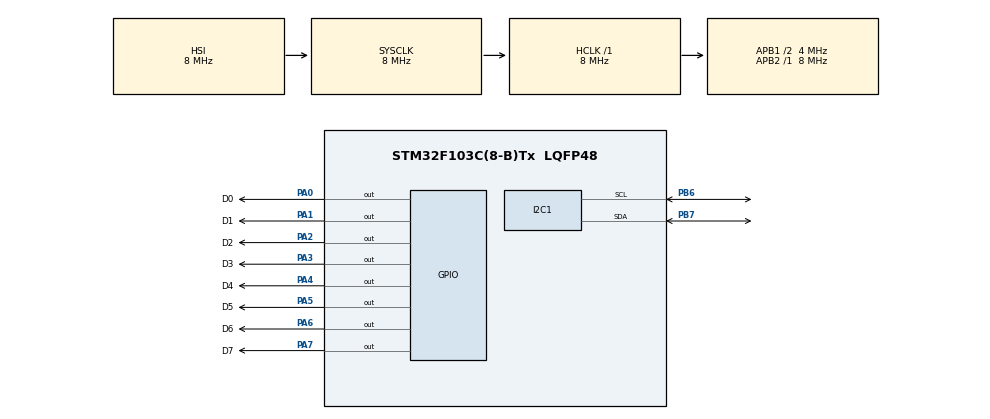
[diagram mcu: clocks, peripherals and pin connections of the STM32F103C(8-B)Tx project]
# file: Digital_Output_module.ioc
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I2C1.I2C_Mode=I2C_Standard
I2C1.OwnAddress=0x14
Mcu.Family=STM32F1
Mcu.Name=STM32F103C(8-B)Tx
Mcu.Package=LQFP48
NVIC.I2C1_ER_IRQn=true\:0\:0\:false\:false\:true\:true\:true\:true
NVIC.I2C1_EV_IRQn=true\:0\:0\:false\:false\:true\:true\:true\:true
NVIC.PriorityGroup=NVIC_PRIORITYGROUP_4
PA0-WKUP.GPIO_Label=D0
PA0-WKUP.Signal=GPIO_Output
PA1.GPIO_Label=D1
PA1.Signal=GPIO_Output
PA13.Mode=Serial_Wire
PA13.Signal=SYS_JTMS-SWDIO
PA14.Mode=Serial_Wire
PA14.Signal=SYS_JTCK-SWCLK
PA2.GPIO_Label=D2
PA2.Signal=GPIO_Output
PA3.GPIO_Label=D3
PA3.Signal=GPIO_Output
PA4.GPIO_Label=D4
PA4.Signal=GPIO_Output
PA5.GPIO_Label=D5
PA5.Signal=GPIO_Output
PA6.GPIO_Label=D6
PA6.Signal=GPIO_Output
PA7.GPIO_Label=D7
PA7.Signal=GPIO_Output
PB6.Mode=I2C
PB6.Signal=I2C1_SCL
PB7.Mode=I2C
PB7.Signal=I2C1_SDA
PC14-OSC32_IN.Mode=LSE-External-Oscillator
PC14-OSC32_IN.Signal=RCC_OSC32_IN
PC15-OSC32_OUT.Mode=LSE-External-Oscillator
PC15-OSC32_OUT.Signal=RCC_OSC32_OUT
PD0-OSC_IN.Mode=HSE-External-Clock-Source
PD0-OSC_IN.Signal=RCC_OSC_IN
PD1-OSC_OUT.Mode=HSE-External-Clock-Source
PD1-OSC_OUT.Signal=RCC_OSC_OUT
ProjectManager.HeapSize=0x200
ProjectManager.StackSize=0x400
ProjectManager.TargetToolchain=STM32CubeIDE
RCC.AHBFreq_Value=8000000
RCC.APB1CLKDivider=RCC_HCLK_DIV2
RCC.APB1Freq_Value=4000000
RCC.APB1TimFreq_Value=8000000
RCC.APB2Freq_Value=8000000
RCC.APB2TimFreq_Value=8000000
RCC.HCLKFreq_Value=8000000
RCC.PLLMUL=RCC_PLL_MUL9
RCC.PLLSourceVirtual=RCC_PLLSOURCE_HSE
RCC.SYSCLKFreq_VALUE=8000000
RCC.USBFreq_Value=72000000
board=custom

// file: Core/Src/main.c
/* USER CODE BEGIN Header */
/**
  ******************************************************************************
  * @file           : main.c
  * @brief          : Main program body
  ******************************************************************************
  * @attention
  *
  * Copyright (c) 2025 STMicroelectronics.
  * All rights reserved.
  *
  * This software is licensed under terms that can be found in the LICENSE file
  * in the root directory of this software component.
  * If no LICENSE file comes with this software, it is provided AS-IS.
  *
  ******************************************************************************
  */
/* USER CODE END Header */
#include "main.h"

/* USER CODE BEGIN Includes */
#include "Data_Output.h"

/* USER CODE END Includes */

I2C_HandleTypeDef hi2c1;

void SystemClock_Config(void);
static void MX_GPIO_Init(void);
static void MX_I2C1_Init(void);

int main(void)
{

  /* MCU Configuration--------------------------------------------------------*/

  /* Reset of all peripherals, Initializes the Flash interface and the Systick. */
  HAL_Init();

  /* Configure the system clock */
  SystemClock_Config();

  /* Initialize all configured peripherals */
  MX_GPIO_Init();
  MX_I2C1_Init();

  /* Infinite loop */
  /* USER CODE BEGIN WHILE */
  while (1)
  {
	  HAL_I2C_EnableListen_IT(&hi2c1);
	  outputs();

    /* USER CODE END WHILE */

  }
}

void SystemClock_Config(void)
{
  RCC_OscInitTypeDef RCC_OscInitStruct = {0};
  RCC_ClkInitTypeDef RCC_ClkInitStruct = {0};

  /** Initializes the RCC Oscillators according to the specified parameters
  * in the RCC_OscInitTypeDef structure.
  */
  RCC_OscInitStruct.OscillatorType = RCC_OSCILLATORTYPE_HSI;
  RCC_OscInitStruct.HSIState = RCC_HSI_ON;
  RCC_OscInitStruct.HSICalibrationValue = RCC_HSICALIBRATION_DEFAULT;
  RCC_OscInitStruct.PLL.PLLState = RCC_PLL_NONE;
  if (HAL_RCC_OscConfig(&RCC_OscInitStruct) != HAL_OK)
  {
    Error_Handler();
  }

  /** Initializes the CPU, AHB and APB buses clocks
  */
  RCC_ClkInitStruct.ClockType = RCC_CLOCKTYPE_HCLK|RCC_CLOCKTYPE_SYSCLK
                              |RCC_CLOCKTYPE_PCLK1|RCC_CLOCKTYPE_PCLK2;
  RCC_ClkInitStruct.SYSCLKSource = RCC_SYSCLKSOURCE_HSI;
  RCC_ClkInitStruct.AHBCLKDivider = RCC_SYSCLK_DIV1;
  RCC_ClkInitStruct.APB1CLKDivider = RCC_HCLK_DIV2;
  RCC_ClkInitStruct.APB2CLKDivider = RCC_HCLK_DIV1;

  if (HAL_RCC_ClockConfig(&RCC_ClkInitStruct, FLASH_LATENCY_0) != HAL_OK)
  {
    Error_Handler();
  }
}

static void MX_I2C1_Init(void)
{

  hi2c1.Instance = I2C1;
  hi2c1.Init.ClockSpeed = 100000;
  hi2c1.Init.DutyCycle = I2C_DUTYCYCLE_2;
  hi2c1.Init.OwnAddress1 = 40;
  hi2c1.Init.AddressingMode = I2C_ADDRESSINGMODE_7BIT;
  hi2c1.Init.DualAddressMode = I2C_DUALADDRESS_DISABLE;
  hi2c1.Init.OwnAddress2 = 0;
  hi2c1.Init.GeneralCallMode = I2C_GENERALCALL_DISABLE;
  hi2c1.Init.NoStretchMode = I2C_NOSTRETCH_DISABLE;
  if (HAL_I2C_Init(&hi2c1) != HAL_OK)
  {
    Error_Handler();
  }

}

static void MX_GPIO_Init(void)
{
  GPIO_InitTypeDef GPIO_InitStruct = {0};

  /* GPIO Ports Clock Enable */
  __HAL_RCC_GPIOC_CLK_ENABLE();
  __HAL_RCC_GPIOD_CLK_ENABLE();
  __HAL_RCC_GPIOA_CLK_ENABLE();
  __HAL_RCC_GPIOB_CLK_ENABLE();

  /*Configure GPIO pin Output Level */
  HAL_GPIO_WritePin(GPIOA, D0_Pin|D1_Pin|D2_Pin|D3_Pin
                          |D4_Pin|D5_Pin|D6_Pin|D7_Pin, GPIO_PIN_RESET);

  /*Configure GPIO pins : D0_Pin D1_Pin D2_Pin D3_Pin
                           D4_Pin D5_Pin D6_Pin D7_Pin */
  GPIO_InitStruct.Pin = D0_Pin|D1_Pin|D2_Pin|D3_Pin
                          |D4_Pin|D5_Pin|D6_Pin|D7_Pin;
  GPIO_InitStruct.Mode = GPIO_MODE_OUTPUT_PP;
  GPIO_InitStruct.Pull = GPIO_NOPULL;
  GPIO_InitStruct.Speed = GPIO_SPEED_FREQ_LOW;
  HAL_GPIO_Init(GPIOA, &GPIO_InitStruct);

}

void Error_Handler(void)
{
  __disable_irq();
  while (1)
  {
  }
}
